AUTOSAR XML (schema 4-3-0)
package /COM/VECTOR/CFG/WORKFLOW/SYSDESC/SYNC
  system SYSTEM: category=ECU_EXTRACT
    system mapping MAPPINGS
      data-mappings:
        data-element=COMPOSITIONTYPE.PpDoorStateRearLeft.DeDoorState, system-signal=sig_State_RearLeftDoor
        data-element=COMPOSITIONTYPE.PpDoorStateRearRight.DeDoorState, system-signal=sig_State_RearRightDoor
        data-element=COMPOSITIONTYPE.PpLightStateRear.DeLightState, system-signal=sig_RearInteriorLight
    root-software-compositions:
      root sw composition prototype COMPOSITIONTYPE: flat-map=FLATMAP, software-composition=COMPOSITIONTYPE
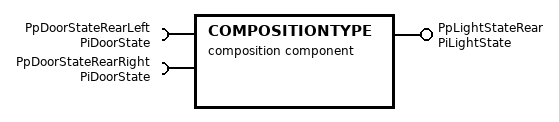
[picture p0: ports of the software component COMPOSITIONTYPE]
  composition sw component type COMPOSITIONTYPE  # UB:Derived from original system description
    require port PpDoorStateRearLeft: nonqueued-receiver-com-spec{data-element=DeDoorState, filter=data-filter-type=ALWAYS, init-value=0}, required-interface=PiDoorState
    require port PpDoorStateRearRight: nonqueued-receiver-com-spec{data-element=DeDoorState, filter=data-filter-type=ALWAYS, init-value=0}, required-interface=PiDoorState
    provide port PpLightStateRear: nonqueued-sender-com-spec{data-element=DeLightState, init-value=0}, provided-interface=PiLightState
    14 x component:
      BswM: type=BswM
      ComM: type=ComM
      Det: type=Det
      EcuM: type=EcuM
      DemMaster_0: type=DemMaster_0
      DemSatellite_0: type=DemSatellite_0
      CpSaDoorFrontLeft: type=CtSaDoor
      CpSaInteriorLightFront: type=CtSaInteriorLight
      CpApMySwc: type=CtApMySwc
      CpSaDoorFrontRight: type=CtSaDoor
      NvM: type=NvM
      CpCddIoHwAb: type=CtCddIoHwAb
      CpSaDisplay: type=CtSaDisplay
      Dcm: type=Dcm
    connect CpApMySwc.PpLightStateFront -> CpSaInteriorLightFront.PpLightState  # UB:Derived from original system description
    connect CpSaDoorFrontLeft.PpDoorState -> CpApMySwc.PpDoorStateFrontLeft  # UB:Derived from original system description
    connect CpSaDoorFrontRight.PpDoorState -> CpApMySwc.PpDoorStateFrontRight  # UB:Derived from original system description
    connect CpCddIoHwAb.PpInteriorLightFront -> CpSaInteriorLightFront.PpInteriorLightIoHwAb  # UB:Derived from original system description
    connect CpCddIoHwAb.PpDoorFrontLeft -> CpSaDoorFrontLeft.PpDoorIoHwAb  # UB:Derived from original system description
    connect CpCddIoHwAb.PpDoorFrontRight -> CpSaDoorFrontRight.PpDoorIoHwAb  # UB:Derived from original system description
    connect CpCddIoHwAb.PpInteriorLightFrontDEFECT -> CpSaInteriorLightFront.PpInteriorLightDefect  # UB:Derived from original system description
    delegate CpApMySwc.PpLightStateRear <-> outer port PpLightStateRear  # UB:Derived from original system description
    delegate CpApMySwc.PpDoorStateRearRight <-> outer port PpDoorStateRearRight  # UB:Derived from original system description
    delegate CpApMySwc.PpDoorStateRearLeft <-> outer port PpDoorStateRearLeft  # UB:Derived from original system description
    connect CpApMySwc.PpDisplayState -> CpSaDisplay.PpDisplayState  # UB:Derived from original system description
    connect CpSaDisplay.PpLocalIgnitionState -> CpApMySwc.PpLocalIgnitionState  # UB:Derived from original system description
    connect CpCddIoHwAb.PpDisplayState -> CpSaDisplay.PpDisplayStateIoHwAb  # UB:Derived from original system description
    connect CpCddIoHwAb.PpLocalClamp15 -> CpSaDisplay.PplocalIgnitionStateIoHwAb  # UB:Derived from original system description
    connect BswM.Switch_ESH_ModeSwitch -> BswM.Notification_ESH_ModeNotification
    connect ComM.UR_USR_INTERIOR_LIGHT -> CpApMySwc.PpComMUserRequestCtApMySwc
    connect CpApMySwc.PpBswMRunRequestCtApMySwc -> BswM.Request_ESH_RunRequest_0
    connect CpApMySwc.PpBswMPostRunRequestCtApMySwc -> BswM.Request_ESH_PostRunRequest_0
    connect ComM.UM_USR_INTERIOR_LIGHT -> CpApMySwc.PpComMCurrentModeCtApMySwc
    connect BswM.Provide_MrpPShutdownTimerDisplay -> CpApMySwc.PpMrpPShutdownTimerDisplayCtApMySwc
    connect BswM.Switch_ESH_ModeSwitch -> CpApMySwc.PpBswMEshModeNotificationCtApMySwc
    connect NvM.PS_CpApMySwcSnNvMPimLightOnOffCounter -> CpApMySwc.PpNvMLightOnOffCtApMySwc
    connect CpApMySwc.PpNvMNotifyJobFinishedOdometerCtApMySwc -> NvM.NvM_RpNotifyJobEnd_CpApMySwcSnNvMPimOdometer
    connect NvM.PS_CpApMySwcSnNvMPimOdometer -> CpApMySwc.PpNvMOdometerCtApMySwc
    connect CpApMySwc.DataServices_Diag_RWDI_LightOnOffCounter_LightOnOffCounter_Value -> Dcm.DataServices_Diag_RWDI_LightOnOffCounter_LightOnOffCounter_Value
    connect CpApMySwc.CBReadData_OccurrenceCounter_OccurenceCounter -> DemMaster_0.CBReadData_OccurrenceCounter_OccurenceCounter
    connect CpApMySwc.CBReadData_OdometerValue_OdometerValue -> DemMaster_0.CBReadData_OdometerValue_OdometerValue
    connect DemMaster_0.OpCycle_IgnitionCycle -> CpApMySwc.OpCycle_IgnitionCycle
    connect DemSatellite_0.Event_DTC_0x000002 -> CpSaInteriorLightFront.Event_DTC_0x000002
  end to end protection set E2EPROTECTIONSET
  port interface mapping set PORTINTERFACEMAPPINGSET
